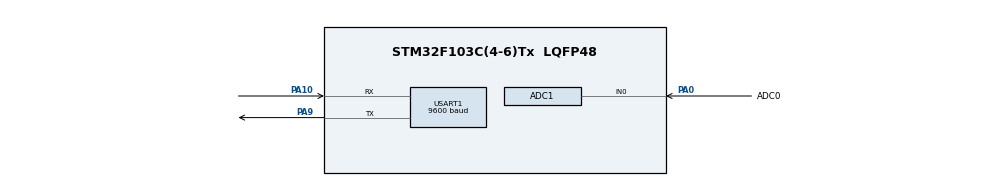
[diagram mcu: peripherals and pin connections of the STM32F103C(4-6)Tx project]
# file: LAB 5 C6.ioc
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ADC1.Channel-1\#ChannelRegularConversion=ADC_CHANNEL_0
ADC1.ContinuousConvMode=ENABLE
ADC1.NbrOfConversionFlag=1
ADC1.Rank-1\#ChannelRegularConversion=1
ADC1.SamplingTime-1\#ChannelRegularConversion=ADC_SAMPLETIME_1CYCLE_5
ADC1.master=1
Mcu.Family=STM32F1
Mcu.Name=STM32F103C(4-6)Tx
Mcu.Package=LQFP48
NVIC.PriorityGroup=NVIC_PRIORITYGROUP_4
NVIC.TIM2_IRQn=true\:0\:0\:false\:false\:true\:true\:true\:true
NVIC.USART1_IRQn=true\:0\:0\:false\:false\:true\:true\:true\:true
PA0-WKUP.GPIO_Label=ADC0
PA0-WKUP.Signal=SharedAnalog_PA0
PA10.Mode=Asynchronous
PA10.Signal=USART1_RX
PA13.Mode=Serial_Wire
PA13.Signal=SYS_JTMS-SWDIO
PA14.Mode=Serial_Wire
PA14.Signal=SYS_JTCK-SWCLK
PA9.Mode=Asynchronous
PA9.Signal=USART1_TX
PD0-OSC_IN.Mode=HSE-External-Oscillator
PD0-OSC_IN.Signal=RCC_OSC_IN
PD1-OSC_OUT.Mode=HSE-External-Oscillator
PD1-OSC_OUT.Signal=RCC_OSC_OUT
ProjectManager.HeapSize=0x200
ProjectManager.StackSize=0x400
ProjectManager.TargetToolchain=STM32CubeIDE
RCC.APB1Freq_Value=8000000
RCC.APB2Freq_Value=8000000
SH.SharedAnalog_PA0.0=GPIO_Analog
SH.SharedAnalog_PA0.1=ADC1_IN0,IN0
TIM2.Period=9
TIM2.Prescaler=7999
USART1.BaudRate=9600
USART1.VirtualMode=VM_ASYNC
VP_TIM2_VS_ClockSourceINT.Mode=Internal
board=custom

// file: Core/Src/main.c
/* USER CODE BEGIN Header */
/**
  ******************************************************************************
  * @file           : main.c
  * @brief          : Main program body
  ******************************************************************************
  * @attention
  *
  * Copyright (c) 2024 STMicroelectronics.
  * All rights reserved.
  *
  * This software is licensed under terms that can be found in the LICENSE file
  * in the root directory of this software component.
  * If no LICENSE file comes with this software, it is provided AS-IS.
  *
  ******************************************************************************
  */
/* USER CODE END Header */
#include "main.h"

/* USER CODE BEGIN Includes */
#include <stdio.h>
#include <string.h>
#include <stdlib.h>
#include <stdint.h>
#include "main.h"
#include "software_timer.h"
/* USER CODE END Includes */

ADC_HandleTypeDef hadc1;

TIM_HandleTypeDef htim2;

UART_HandleTypeDef huart1;

/* USER CODE BEGIN PV */
#define MAX_BUFFER_SIZE 31 //0-29 //one '/0'
#define COMMAND_RST "!RST#"
#define COMMAND_OK "!OK#"
#define TIMEOUT_PERIOD 3000 // 3 seconds in milliseconds

uint8_t temp = 0;
uint8_t buffer[MAX_BUFFER_SIZE];
uint8_t index_buffer = 0;
uint8_t buffer_flag = 0;
uint8_t command_flag = 0;
char command_data[MAX_BUFFER_SIZE];
uint32_t ADC_value = 0;
//char str[30];
/* USER CODE END PV */

void SystemClock_Config(void);
static void MX_GPIO_Init(void);
static void MX_TIM2_Init(void);
static void MX_ADC1_Init(void);
static void MX_USART1_UART_Init(void);

/* USER CODE BEGIN 0 */
uint32_t ReadADC(void) {
    uint32_t adcValue = 0;

    // Start the ADC conversion
    HAL_ADC_Start(&hadc1);

    // Poll for conversion completion
    if (HAL_ADC_PollForConversion(&hadc1, HAL_MAX_DELAY) == HAL_OK) {
        // Get the ADC value
        adcValue = HAL_ADC_GetValue(&hadc1);
    }

    // Stop the ADC
    HAL_ADC_Stop(&hadc1);

    return adcValue;
}

void HAL_UART_RxCpltCallback(UART_HandleTypeDef *huart) {
    if (huart->Instance == USART1) {
        // Store the received character
        buffer[index_buffer] = temp;

        // Check if we received a complete command (ends with '#')
        if (temp == '#') {
            buffer_flag = 1;
            // Ensure there's space for null terminator
            if (index_buffer < MAX_BUFFER_SIZE - 1) {
                buffer[index_buffer + 1] = '\0';
            }
        }

        // Increment index, checking for buffer wrap
        index_buffer++;
        if (index_buffer >= MAX_BUFFER_SIZE - 1) { // Buffer is full
            index_buffer = 0;
        }

        // Continue receiving
        HAL_UART_Receive_IT(&huart1, &temp, 1);
    }
}

typedef enum {
    COMMAND_TYPE_NONE,
    COMMAND_TYPE_RST,
    COMMAND_TYPE_OK
} CommandType;

void command_parser_fsm(void) {
     CommandType detectedCommand = COMMAND_TYPE_NONE;

     if (strstr((char*)buffer, COMMAND_RST) != NULL) {
         detectedCommand = COMMAND_TYPE_RST;
     } else if (strstr((char*)buffer, COMMAND_OK) != NULL) {
         detectedCommand = COMMAND_TYPE_OK;
     }

   switch (detectedCommand) {
        case COMMAND_TYPE_RST:
            command_flag = 1; // Set flag for reset command
            // Debug message for command received
            char debug_msg_rst[50];
            snprintf(debug_msg_rst, sizeof(debug_msg_rst), "Received !RST# command\n");
            HAL_UART_Transmit(&huart1, (uint8_t*)debug_msg_rst, strlen(debug_msg_rst), HAL_MAX_DELAY);
            break;
        case COMMAND_TYPE_OK:
            command_flag = 0; // Reset flag for OK command
            // Debug message for command received
            char debug_msg_ok[50];
            snprintf(debug_msg_ok, sizeof(debug_msg_ok), "Received !OK# command\n");
            HAL_UART_Transmit(&huart1, (uint8_t*)debug_msg_ok, strlen(debug_msg_ok), HAL_MAX_DELAY);
            break;
        default:
            break;
    }

    // Clear the buffer and reset the index

        memset(buffer, 0, sizeof(buffer));
        index_buffer = 0;

}

void uart_communication_fsm(void) {
    // Read the current ADC value
    ADC_value =ReadADC();

    // Check the command flag status
    if (command_flag == 1) { // Command "!RST#" received
        // Format the ADC value into a command string
        snprintf(command_data, sizeof(command_data), "!ADC=%lu#\r\n", ADC_value);

        // Transmit the command data over UART
        HAL_UART_Transmit(&huart1, (uint8_t*)command_data, strlen(command_data), HAL_MAX_DELAY);

        // Update the command flag to indicate waiting for "!OK#"
        command_flag = 2;

        // Set a timeout period for waiting
        setTimer0(TIMEOUT_PERIOD);

        // Debug message
        //char debug_msg[50];
        //snprintf(debug_msg, sizeof(debug_msg), "Command flag set to 2, timer0 set to 100\n");
        //HAL_UART_Transmit(&huart1, (uint8_t*)debug_msg, strlen(debug_msg), HAL_MAX_DELAY);
    } else if (command_flag == 2) { // Waiting for "!OK#"
        // Check if the timeout period has elapsed
        if (timer0_flag == 1) {
            // Retransmit the command data over UART
            HAL_UART_Transmit(&huart1, (uint8_t*)command_data, strlen(command_data), HAL_MAX_DELAY);

            // Reset the timeout period
            setTimer0(TIMEOUT_PERIOD); //TIMEOUT_PERIOD

            // Reset the timer0_flag
            //timer0_flag = 0;

            // Debug message
            //char debug_msg[50];
            //snprintf(debug_msg, sizeof(debug_msg), "Retransmitting command data, timer0 reset to 100\n");
           // HAL_UART_Transmit(&huart1, (uint8_t*)debug_msg, strlen(debug_msg), HAL_MAX_DELAY);
        }
    }
}

/* USER CODE END 0 */

int main(void)
{

  /* MCU Configuration--------------------------------------------------------*/

  /* Reset of all peripherals, Initializes the Flash interface and the Systick. */
  HAL_Init();

  /* Configure the system clock */
  SystemClock_Config();

  /* Initialize all configured peripherals */
  MX_GPIO_Init();
  MX_TIM2_Init();
  MX_ADC1_Init();
  MX_USART1_UART_Init();
  /* USER CODE BEGIN 2 */
  HAL_TIM_Base_Start_IT(&htim2);

  // snprintf(str, sizeof(str), "%lu", ADC_value);
  // HAL_UART_Transmit(&huart1, (uint8_t*)str, strlen(str), HAL_MAX_DELAY);
  /* USER CODE END 2 */

  /* Infinite loop */
  /* USER CODE BEGIN WHILE */

  HAL_UART_Receive_IT(&huart1, &temp, 1);
  while (1)
  {
        if (buffer_flag == 1) {
            command_parser_fsm();
            buffer_flag = 0;
        }
        uart_communication_fsm();

        // // Transmit "hello" over UART
        // const char *message = "hello\r\n"; // Message to send
        // HAL_UART_Transmit(&huart1, (uint8_t*)message, strlen(message), HAL_MAX_DELAY);

        // // Optional: Add a delay to avoid flooding the UART
        // HAL_Delay(1000); // Delay for 1 second

    /* USER CODE END WHILE */

  }
}

void SystemClock_Config(void)
{
  RCC_OscInitTypeDef RCC_OscInitStruct = {0};
  RCC_ClkInitTypeDef RCC_ClkInitStruct = {0};
  RCC_PeriphCLKInitTypeDef PeriphClkInit = {0};

  /** Initializes the RCC Oscillators according to the specified parameters
  * in the RCC_OscInitTypeDef structure.
  */
  RCC_OscInitStruct.OscillatorType = RCC_OSCILLATORTYPE_HSI;
  RCC_OscInitStruct.HSIState = RCC_HSI_ON;
  RCC_OscInitStruct.HSICalibrationValue = RCC_HSICALIBRATION_DEFAULT;
  RCC_OscInitStruct.PLL.PLLState = RCC_PLL_NONE;
  if (HAL_RCC_OscConfig(&RCC_OscInitStruct) != HAL_OK)
  {
    Error_Handler();
  }

  /** Initializes the CPU, AHB and APB buses clocks
  */
  RCC_ClkInitStruct.ClockType = RCC_CLOCKTYPE_HCLK|RCC_CLOCKTYPE_SYSCLK
                              |RCC_CLOCKTYPE_PCLK1|RCC_CLOCKTYPE_PCLK2;
  RCC_ClkInitStruct.SYSCLKSource = RCC_SYSCLKSOURCE_HSI;
  RCC_ClkInitStruct.AHBCLKDivider = RCC_SYSCLK_DIV1;
  RCC_ClkInitStruct.APB1CLKDivider = RCC_HCLK_DIV1;
  RCC_ClkInitStruct.APB2CLKDivider = RCC_HCLK_DIV1;

  if (HAL_RCC_ClockConfig(&RCC_ClkInitStruct, FLASH_LATENCY_0) != HAL_OK)
  {
    Error_Handler();
  }
  PeriphClkInit.PeriphClockSelection = RCC_PERIPHCLK_ADC;
  PeriphClkInit.AdcClockSelection = RCC_ADCPCLK2_DIV2;
  if (HAL_RCCEx_PeriphCLKConfig(&PeriphClkInit) != HAL_OK)
  {
    Error_Handler();
  }
}

static void MX_ADC1_Init(void)
{

  ADC_ChannelConfTypeDef sConfig = {0};

  /** Common config
  */
  hadc1.Instance = ADC1;
  hadc1.Init.ScanConvMode = ADC_SCAN_DISABLE;
  hadc1.Init.ContinuousConvMode = ENABLE;
  hadc1.Init.DiscontinuousConvMode = DISABLE;
  hadc1.Init.ExternalTrigConv = ADC_SOFTWARE_START;
  hadc1.Init.DataAlign = ADC_DATAALIGN_RIGHT;
  hadc1.Init.NbrOfConversion = 1;
  if (HAL_ADC_Init(&hadc1) != HAL_OK)
  {
    Error_Handler();
  }

  /** Configure Regular Channel
  */
  sConfig.Channel = ADC_CHANNEL_0;
  sConfig.Rank = ADC_REGULAR_RANK_1;
  sConfig.SamplingTime = ADC_SAMPLETIME_1CYCLE_5;
  if (HAL_ADC_ConfigChannel(&hadc1, &sConfig) != HAL_OK)
  {
    Error_Handler();
  }

}

static void MX_TIM2_Init(void)
{

  TIM_ClockConfigTypeDef sClockSourceConfig = {0};
  TIM_MasterConfigTypeDef sMasterConfig = {0};

  htim2.Instance = TIM2;
  htim2.Init.Prescaler = 7999;
  htim2.Init.CounterMode = TIM_COUNTERMODE_UP;
  htim2.Init.Period = 9;
  htim2.Init.ClockDivision = TIM_CLOCKDIVISION_DIV1;
  htim2.Init.AutoReloadPreload = TIM_AUTORELOAD_PRELOAD_DISABLE;
  if (HAL_TIM_Base_Init(&htim2) != HAL_OK)
  {
    Error_Handler();
  }
  sClockSourceConfig.ClockSource = TIM_CLOCKSOURCE_INTERNAL;
  if (HAL_TIM_ConfigClockSource(&htim2, &sClockSourceConfig) != HAL_OK)
  {
    Error_Handler();
  }
  sMasterConfig.MasterOutputTrigger = TIM_TRGO_RESET;
  sMasterConfig.MasterSlaveMode = TIM_MASTERSLAVEMODE_DISABLE;
  if (HAL_TIMEx_MasterConfigSynchronization(&htim2, &sMasterConfig) != HAL_OK)
  {
    Error_Handler();
  }

}

static void MX_USART1_UART_Init(void)
{

  huart1.Instance = USART1;
  huart1.Init.BaudRate = 9600;
  huart1.Init.WordLength = UART_WORDLENGTH_8B;
  huart1.Init.StopBits = UART_STOPBITS_1;
  huart1.Init.Parity = UART_PARITY_NONE;
  huart1.Init.Mode = UART_MODE_TX_RX;
  huart1.Init.HwFlowCtl = UART_HWCONTROL_NONE;
  huart1.Init.OverSampling = UART_OVERSAMPLING_16;
  if (HAL_UART_Init(&huart1) != HAL_OK)
  {
    Error_Handler();
  }

}

static void MX_GPIO_Init(void)
{

  /* GPIO Ports Clock Enable */
  __HAL_RCC_GPIOD_CLK_ENABLE();
  __HAL_RCC_GPIOA_CLK_ENABLE();

}

/* USER CODE BEGIN 4 */
void HAL_TIM_PeriodElapsedCallback(TIM_HandleTypeDef *htim) {
    timer_run();
}
/* USER CODE END 4 */

void Error_Handler(void)
{
  __disable_irq();
  while (1)
  {
  }
}
